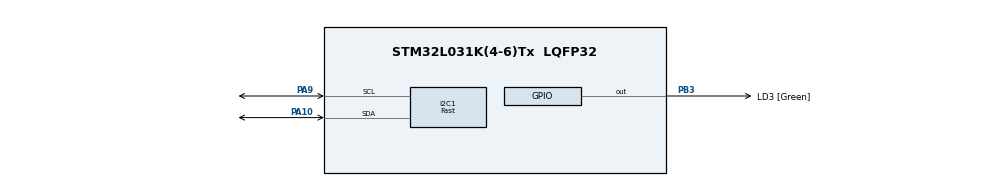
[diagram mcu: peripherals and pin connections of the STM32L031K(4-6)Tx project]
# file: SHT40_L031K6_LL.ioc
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CRC.CRCLength=CRC_POLYLENGTH_8B
CRC.DefaultInitValueUse=DEFAULT_INIT_VALUE_ENABLE
CRC.DefaultPolynomialUse=DEFAULT_POLYNOMIAL_DISABLE
CRC.GeneratingPolynomial=X5+X4+X0
CRC.OutputDataInversionMode=CRC_OUTPUTDATA_INVERSION_DISABLE
I2C1.Analog_Filter=I2C_ANALOGFILTER_ENABLE
I2C1.I2C_Speed_Mode=I2C_Fast
I2C1.Timing=0x0060112F
Mcu.Family=STM32L0
Mcu.Name=STM32L031K(4-6)Tx
Mcu.Package=LQFP32
PA10.Mode=I2C
PA10.Signal=I2C1_SDA
PA13.GPIO_Label=TMS
PA13.Mode=Serial_Wire
PA13.Signal=SYS_SWDIO
PA14.GPIO_Label=TCK
PA14.Mode=Serial_Wire
PA14.Signal=SYS_SWCLK
PA9.Mode=I2C
PA9.Signal=I2C1_SCL
PB3.GPIO_Label=LD3 [Green]
PB3.Signal=GPIO_Output
PC14-OSC32_IN.Mode=LSE-External-Oscillator
PC14-OSC32_IN.Signal=RCC_OSC32_IN
PC15-OSC32_OUT.Mode=LSE-External-Oscillator
PC15-OSC32_OUT.Signal=RCC_OSC32_OUT
ProjectManager.HeapSize=0x200
ProjectManager.StackSize=0x400
ProjectManager.TargetToolchain=STM32CubeIDE
RCC.AHBFreq_Value=32000000
RCC.APB1Freq_Value=32000000
RCC.APB1TimFreq_Value=32000000
RCC.APB2Freq_Value=32000000
RCC.APB2TimFreq_Value=32000000
RCC.HCLKFreq_Value=32000000
RCC.HSE_VALUE=8000000
RCC.HSI16_VALUE=16000000
RCC.HSI48_VALUE=48000000
RCC.HSI_VALUE=16000000
RCC.MSI_VALUE=2097000
RCC.PLLMUL=RCC_PLLMUL_4
RCC.SYSCLKFreq_VALUE=32000000
RCC.SYSCLKSource=RCC_SYSCLKSOURCE_PLLCLK
RCC.VCOOutputFreq_Value=64000000
TIM2.Prescaler=32
VP_CRC_VS_CRC.Mode=CRC_Activate
VP_TIM2_VS_ClockSourceINT.Mode=Internal
board=NUCLEO-L031K6

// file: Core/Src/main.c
/* USER CODE BEGIN Header */
/**
  ******************************************************************************
  * @file           : main.c
  * @brief          : Main program body
  ******************************************************************************
  * @attention
  *
  * Copyright (c) 2024 STMicroelectronics.
  * All rights reserved.
  *
  * This software is licensed under terms that can be found in the LICENSE file
  * in the root directory of this software component.
  * If no LICENSE file comes with this software, it is provided AS-IS.
  *
  ******************************************************************************
  */
/* USER CODE END Header */
#include "main.h"
#include "crc.h"
#include "i2c.h"
#include "tim.h"
#include "gpio.h"

/* USER CODE BEGIN Includes */
#include "sht4x.h"
/* USER CODE END Includes */

/* USER CODE BEGIN PV */
Sht4xStatus sht4x_status;
Sht4xRawData sht4x_raw_data;
Sht4xData sht4x_data;
Sht4xDevice sht4x = {
		.i2c_address = SHT4X_I2C_ADDR_A,
		.i2c_write = &I2C1_transmit,
		.i2c_read = &I2C1_receive,
		.calculate_crc = &calculate_CRC8
};
/* USER CODE END PV */

void SystemClock_Config(void);

int main(void)
{

  /* MCU Configuration--------------------------------------------------------*/

  /* Reset of all peripherals, Initializes the Flash interface and the Systick. */
  LL_APB2_GRP1_EnableClock(LL_APB2_GRP1_PERIPH_SYSCFG);
  LL_APB1_GRP1_EnableClock(LL_APB1_GRP1_PERIPH_PWR);

  /* Configure the system clock */
  SystemClock_Config();

  /* Initialize all configured peripherals */
  MX_GPIO_Init();
  MX_I2C1_Init();
  MX_CRC_Init();
  MX_TIM2_Init();
  /* USER CODE BEGIN 2 */
  LL_I2C_Enable(I2C1);
  /* USER CODE END 2 */

  /* Infinite loop */
  /* USER CODE BEGIN WHILE */
  while (1)
  {
	  sht4x_send_command(&sht4x, SHT4X_I2C_CMD_MEAS_HIGH_PREC);
	  LL_mDelay(9);
	  sht4x_status = sht4x_read_and_check_measurement(&sht4x, &sht4x_data);

	  LL_mDelay(100);
    /* USER CODE END WHILE */

  }
}

void SystemClock_Config(void)
{
  LL_FLASH_SetLatency(LL_FLASH_LATENCY_1);
  while(LL_FLASH_GetLatency()!= LL_FLASH_LATENCY_1)
  {
  }
  LL_PWR_SetRegulVoltageScaling(LL_PWR_REGU_VOLTAGE_SCALE1);
  while (LL_PWR_IsActiveFlag_VOS() != 0)
  {
  }
  LL_RCC_HSI_Enable();

   /* Wait till HSI is ready */
  while(LL_RCC_HSI_IsReady() != 1)
  {

  }
  LL_RCC_HSI_SetCalibTrimming(16);
  LL_RCC_PLL_ConfigDomain_SYS(LL_RCC_PLLSOURCE_HSI, LL_RCC_PLL_MUL_4, LL_RCC_PLL_DIV_2);
  LL_RCC_PLL_Enable();

   /* Wait till PLL is ready */
  while(LL_RCC_PLL_IsReady() != 1)
  {

  }
  LL_RCC_SetAHBPrescaler(LL_RCC_SYSCLK_DIV_1);
  LL_RCC_SetAPB1Prescaler(LL_RCC_APB1_DIV_1);
  LL_RCC_SetAPB2Prescaler(LL_RCC_APB2_DIV_1);
  LL_RCC_SetSysClkSource(LL_RCC_SYS_CLKSOURCE_PLL);

   /* Wait till System clock is ready */
  while(LL_RCC_GetSysClkSource() != LL_RCC_SYS_CLKSOURCE_STATUS_PLL)
  {

  }

  LL_Init1msTick(32000000);

  LL_SetSystemCoreClock(32000000);
  LL_RCC_SetI2CClockSource(LL_RCC_I2C1_CLKSOURCE_PCLK1);
}

void Error_Handler(void)
{
  __disable_irq();
  while (1)
  {
  }
}
